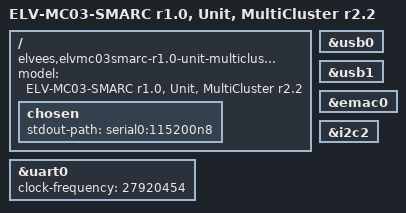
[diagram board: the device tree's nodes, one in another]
// SPDX-License-Identifier: GPL-2.0+
// Copyright 2021-2026 RnD Center "ELVEES", JSC

/dts-v1/;

#include "mcom03-elvmc03smarc-r1.0.dtsi"

/ {
	model = "ELV-MC03-SMARC r1.0, Unit, MultiCluster r2.2";
	compatible = "elvees,elvmc03smarc-r1.0-unit-multicluster-r2.2",
		     "elvees,elvmc03smarc-unit-multicluster",
		     "elvees,unit-multicluster-r2.2",
		     "elvees,elvmc03smarc-r1.0",
		     "elvees,elvmc03smarc",
		     "elvees,mcom03";

	chosen {
		stdout-path = "serial0:115200n8";
	};
};

&uart0 {
	status = "okay";
	clock-frequency = <27920454>;
};

/* Connected to USB 3.0 Type-A */
&usb0 {
	status = "okay";
};

/* Connected to USB hub on ELV-MC03-SMARC
 * TODO: Move to mcom03-elvmc03smarc-r1.0.dtsi */
&usb1 {
	status = "okay";
};

/* Connected to RJ-45 */
&emac0 {
	status = "okay";
};

&i2c2 {
	status = "okay";
};
